# ADuCM4050 register map
Vendor: Analog Devices; Series: ADuCM4050; File version: 1p0
CPU: CM4 r0p1, little endian, MPU, FPU, 3 interrupt priority bits
Registers are 32-bit, read-write, reset 0x0 unless marked. A register's access mark holds for its fields unless they carry their own. Offsets are from the block's base; [hi:lo] are bit positions.

## UART0 — Universal Asynchronous Receiver/Transmitter
Base 0x40005000
Same registers: UART1 0x40005400
0x00 RX 16-bit — Receive Buffer Register
  [7:0] RBR ro
0x00 TX 16-bit (alternate view of RX) — Transmit Holding Register
  [7:0] THR wo range 0x00000000..0x000000FF
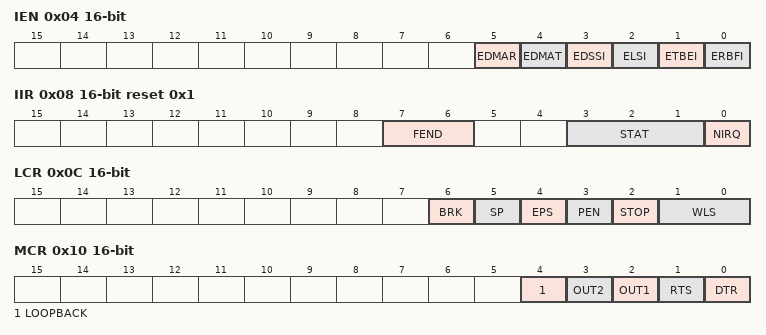
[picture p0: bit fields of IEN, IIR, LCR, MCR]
0x04 IEN 16-bit — Interrupt Enable
  [5] EDMAR — DMA Requests in Receive Mode
  [4] EDMAT — DMA Requests in Transmit Mode
  [3] EDSSI — Modem Status Interrupt
  [2] ELSI — Rx Status Interrupt
  [1] ETBEI — Transmit Buffer Empty Interrupt
  [0] ERBFI — Receive Buffer Full Interrupt
0x08 IIR 16-bit reset 0x1 — Interrupt ID
  [7:6] FEND ro — FIFO Enabled
  [3:1] STAT ro — Interrupt Status
    0=STAT_EDSSI (Modem status interrupt (Read MSR register to clear)); 1=STAT_ETBEI (Transmit buffer empty interrupt (Write to Tx register or read IIR register to clear)); 2=STAT_ERBFI (Receive buffer full interrupt (Read Rx register to clear)); 3=STAT_RLSI (Receive line status interrupt (Read LSR register to clear)); 6=STAT_RFTOI (Receive FIFO time-out interrupt (Read Rx register to clear))
  [0] NIRQ ro — Interrupt Flag
0x0C LCR 16-bit — Line Control
  [6] BRK — Set Break
  [5] SP — Stick Parity
    0=PAR_NOTFORCED (Parity will not be forced based on Parity Select and Parity Enable bits.); 1=PAR_FORCED (Parity forced based on Parity Select and Parity Enable bits.)
  [4] EPS — Parity Select
  [3] PEN — Parity Enable
  [2] STOP — Stop Bit
  [1:0] WLS — Word Length Select
0x10 MCR 16-bit — Modem Control
  [4] LOOPBACK — Loopback Mode
  [3] OUT2 — Output 2
  [2] OUT1 — Output 1
  [1] RTS — Request to Send
  [0] DTR — Data Terminal Ready
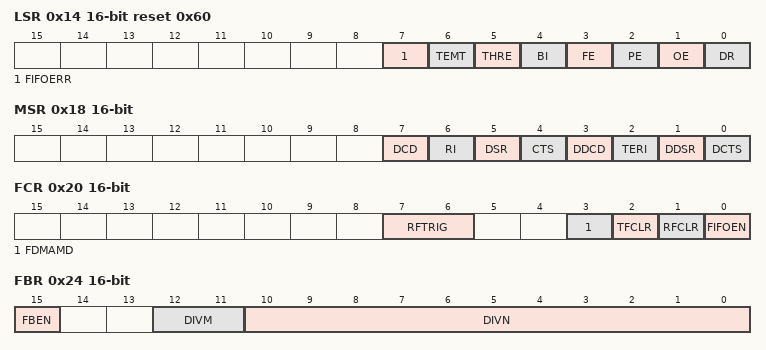
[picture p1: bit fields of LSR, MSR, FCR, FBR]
0x14 LSR 16-bit reset 0x60 — Line Status
  [7] FIFOERR ro — Rx FIFO Parity Error/Frame Error/Break Indication
  [6] TEMT ro — Transmit and Shift Register Empty Status
  [5] THRE ro — Transmit Register Empty
  [4] BI ro — Break Indicator
  [3] FE ro — Framing Error
  [2] PE ro — Parity Error
  [1] OE ro — Overrun Error
  [0] DR ro — Data Ready
0x18 MSR 16-bit — Modem Status
  [7] DCD ro — Data Carrier Detect
  [6] RI ro — Ring Indicator
  [5] DSR ro — Data Set Ready
  [4] CTS ro — Clear to Send
  [3] DDCD ro — Delta DCD
  [2] TERI ro — Trailing Edge RI
  [1] DDSR ro — Delta DSR
  [0] DCTS ro — Delta CTS
0x1C SCR 16-bit — Scratch Buffer
  [7:0] SCR range 0x00000000..0x000000FF — Scratch
0x20 FCR 16-bit — FIFO Control
  [7:6] RFTRIG — Rx FIFO Trigger Level
  [3] FDMAMD — FIFO DMA Mode
    0=MODE0 (In DMA mode 0, RX DMA request will be asserted whenever there's data in RBR or RX FIFO and de-assert whenever RBR or RX FIFO is empty; TX DMA request will be asserted whenever THR or TX FIFO is empty and de-assert whenever data written to.); 1=MODE1 (in DMA mode 1, RX DMA request will be asserted whenever RX FIFO trig level or time out reached and de-assert thereafter when RX FIFO is empty; TX DMA request will be asserted whenever TX FIFO is empty and de-assert thereafter when TX FIFO is completely filled up full.)
  [2] TFCLR wo range 0x00000000..0x00000001 — Clear Tx FIFO
  [1] RFCLR wo range 0x00000000..0x00000001 — Clear Rx FIFO
  [0] FIFOEN range 0x00000000..0x00000001 — FIFO Enable as to Work in 16550 Mode
0x24 FBR 16-bit — Fractional Baud Rate
  [15] FBEN range 0x00000000..0x00000001 — Fractional Baud Rate Generator Enable
  [12:11] DIVM range 0x00000000..0x00000003 — Fractional Baud Rate M Divide Bits 1 to 3
  [10:0] DIVN range 0x00000000..0x000007FF — Fractional Baud Rate N Divide Bits 0 to 2047
0x28 DIV 16-bit — Baud Rate Divider
  [15:0] DIV range 0x00000000..0x0000FFFF
0x2C LCR2 16-bit reset 0x2 — Second Line Control
  [1:0] OSR — Over Sample Rate
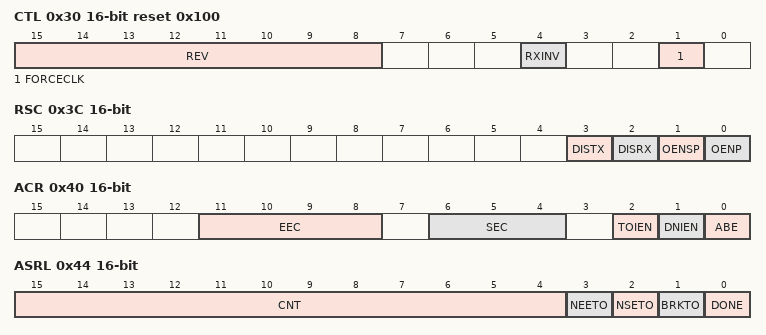
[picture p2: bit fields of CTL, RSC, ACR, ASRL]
0x30 CTL 16-bit reset 0x100 — UART Control Register
  [15:8] REV ro — UART Revision ID
  [4] RXINV — Invert Receiver Line
    0=NOTINV_RX (Don't invert receiver line (idling high).); 1=INV_RX (Invert receiver line (idling low).)
  [1] FORCECLK — Force UCLK on
0x34 RFC 16-bit — RX FIFO Byte Count
  [4:0] RFC ro — Current Rx FIFO Data Bytes
0x38 TFC 16-bit — TX FIFO Byte Count
  [4:0] TFC ro — Current Tx FIFO Data Bytes
0x3C RSC 16-bit — RS485 Half-duplex Control
  [3] DISTX range 0x00000000..0x00000001 — Hold off Tx When Receiving
  [2] DISRX range 0x00000000..0x00000001 — Disable Rx When Transmitting
  [1] OENSP — SOUT_EN De-assert Before Full Stop Bit(s)
  [0] OENP — SOUT_EN Polarity
0x40 ACR 16-bit — Auto Baud Control
  [11:8] EEC — Ending Edge Count
    0=EEC_EDGE1 (First edge); 1=EEC_EDGE2 (Second edge); 2=EEC_EDGE3 (Third edge); 3=EEC_EDGE4 (Fourth edge); 4=EEC_EDGE5 (Fifth edge); 5=EEC_EDGE6 (Sixth edge); 6=EEC_EDGE7 (Seventh edge); 7=EEC_EDGE8 (Eighth edge); 8=EEC_EDGE9 (Ninth edge)
  [6:4] SEC — Starting Edge Count
    0=SEC_EDGE1 (First edge); 1=SEC_EDGE2 (Second edge); 2=SEC_EDGE3 (Third edge); 3=SEC_EDGE4 (Fourth edge); 4=SEC_EDGE5 (Fifth edge); 5=SEC_EDGE6 (Sixth edge); 6=SEC_EDGE7 (Seventh edge); 7=SEC_EDGE8 (Eighth edge)
  [2] TOIEN — Enable Time-out Interrupt
    0=DIS_TIMEOUTINT (Disable timeout interrupt); 1=EN_TIMEOUTINT (Enable timeout interrupt)
  [1] DNIEN — Enable Done Interrupt
    0=DIS_DONEINT (Disable done interrupt); 1=EN_DONEINT (Enable done interrupt)
  [0] ABE — Auto Baud Enable
    0=DIS_AUTOBAUD (Disable auto baudrate); 1=EN_AUTOBAUD (Enable auto baudrate)
0x44 ASRL 16-bit — Auto Baud Status (Low)
  [15:4] CNT ro — CNT[11:0] Auto Baud Counter Value
  [3] NEETO ro — Timed Out Due to No Valid Ending Edge Found
  [2] NSETO ro — Timed Out Due to No Valid Start Edge Found
  [1] BRKTO ro — Timed Out Due to Long Time Break Condition
  [0] DONE ro — Auto Baud Done Successfully
0x48 ASRH 16-bit — Auto Baud Status (High)
  [7:0] CNT ro — CNT[19:12] Auto Baud Counter Value

## Notices in the file
Copyright (c) 2014-2017 Analog Devices, Inc.  All Rights Reserved.
This software is proprietary and confidential to Analog Devices, Inc.
and its licensors.
